AUTOSAR XML (schema 4-2-2)
standard types defined: void, boolean, sint8, sint16, sint32, sint64, uint8, uint16, uint32, uint64, float32, float64
package /Components/PhysicalDimensions
  physical dimension PhysicalDimension_None: length-exp=0.0, mass-exp=0.0, time-exp=0.0, current-exp=0.0, temperature-exp=0.0, molar-amount-exp=0.0, luminous-intensity-exp=0.0
package /Components/Units
  unit Unit_None: display-name=-, factor-si-to-unit=1.0, offset-si-to-unit=0.0, physical-dimension=PhysicalDimension_None
package /Components/ApplicationTypes
  32 x app type, all with compu {phys=raw for raw 0}, range raw 0, unit=-:
    wLoad_Type_{1..7}: category=VALUE
    wLoad_Type_8: category=BOOLEAN
    wLoad_Type_{9..15}: category=VALUE
    wLoad_Type_16: category=BOOLEAN
    AMOS_APP4UCU_Type_{17..23}: category=VALUE
    AMOS_APP4UCU_Type_24: category=BOOLEAN
    AMOS_APP4UCU_Type_{25..31}: category=VALUE
    AMOS_APP4UCU_Type_32: category=BOOLEAN
package /Components/TypeMappings
  data type mapping set TypeMapping
    data-type-maps:
      application-data-type=wLoad_Type_1, implementation-data-type=uint8
      application-data-type=wLoad_Type_2, implementation-data-type=sint8
      application-data-type=wLoad_Type_3, implementation-data-type=uint16
      application-data-type=wLoad_Type_4, implementation-data-type=sint16
      application-data-type=wLoad_Type_5, implementation-data-type=uint32
      application-data-type=wLoad_Type_6, implementation-data-type=sint32
      application-data-type=wLoad_Type_7, implementation-data-type=float32
      application-data-type=wLoad_Type_8, implementation-data-type=boolean
      application-data-type=wLoad_Type_9, implementation-data-type=uint8
      application-data-type=wLoad_Type_10, implementation-data-type=sint8
      application-data-type=wLoad_Type_11, implementation-data-type=uint16
      application-data-type=wLoad_Type_12, implementation-data-type=sint16
      application-data-type=wLoad_Type_13, implementation-data-type=uint32
      application-data-type=wLoad_Type_14, implementation-data-type=sint32
      application-data-type=wLoad_Type_15, implementation-data-type=float32
      application-data-type=wLoad_Type_16, implementation-data-type=boolean
      application-data-type=AMOS_APP4UCU_Type_17, implementation-data-type=uint8
      application-data-type=AMOS_APP4UCU_Type_18, implementation-data-type=sint8
      application-data-type=AMOS_APP4UCU_Type_19, implementation-data-type=uint16
      application-data-type=AMOS_APP4UCU_Type_20, implementation-data-type=sint16
      application-data-type=AMOS_APP4UCU_Type_21, implementation-data-type=uint32
      application-data-type=AMOS_APP4UCU_Type_22, implementation-data-type=sint32
      application-data-type=AMOS_APP4UCU_Type_23, implementation-data-type=float32
      application-data-type=AMOS_APP4UCU_Type_24, implementation-data-type=boolean
      application-data-type=AMOS_APP4UCU_Type_25, implementation-data-type=uint8
      application-data-type=AMOS_APP4UCU_Type_26, implementation-data-type=sint8
      application-data-type=AMOS_APP4UCU_Type_27, implementation-data-type=uint16
      application-data-type=AMOS_APP4UCU_Type_28, implementation-data-type=sint16
      application-data-type=AMOS_APP4UCU_Type_29, implementation-data-type=uint32
      application-data-type=AMOS_APP4UCU_Type_30, implementation-data-type=sint32
      application-data-type=AMOS_APP4UCU_Type_31, implementation-data-type=float32
      application-data-type=AMOS_APP4UCU_Type_32, implementation-data-type=boolean
package /Components/PortInterfaces
  4 x sender receiver interface:
    wLoad_toApp
      8 x data, all with sw-calibration-access=READ-ONLY:
        test_u8: type=wLoad_Type_1
        test_i8: type=wLoad_Type_2
        test_u16: type=wLoad_Type_3
        test_i16: type=wLoad_Type_4
        test_u32: type=wLoad_Type_5
        test_i32: type=wLoad_Type_6
        test_r32: type=wLoad_Type_7
        test_b: type=wLoad_Type_8
    wLoad_fromApp
      8 x data, all with sw-calibration-access=READ-ONLY:
        test_u8: type=wLoad_Type_9
        test_i8: type=wLoad_Type_10
        test_u16: type=wLoad_Type_11
        test_i16: type=wLoad_Type_12
        test_u32: type=wLoad_Type_13
        test_i32: type=wLoad_Type_14
        test_r32: type=wLoad_Type_15
        test_b: type=wLoad_Type_16
    AMOS_APP4UCU_fromApp
      8 x data, all with sw-calibration-access=READ-ONLY:
        test_u8: type=AMOS_APP4UCU_Type_17
        test_i8: type=AMOS_APP4UCU_Type_18
        test_u16: type=AMOS_APP4UCU_Type_19
        test_i16: type=AMOS_APP4UCU_Type_20
        test_u32: type=AMOS_APP4UCU_Type_21
        test_i32: type=AMOS_APP4UCU_Type_22
        test_r32: type=AMOS_APP4UCU_Type_23
        test_b: type=AMOS_APP4UCU_Type_24
    AMOS_APP4UCU_toApp
      8 x data, all with sw-calibration-access=READ-ONLY:
        test_u8: type=AMOS_APP4UCU_Type_25
        test_i8: type=AMOS_APP4UCU_Type_26
        test_u16: type=AMOS_APP4UCU_Type_27
        test_i16: type=AMOS_APP4UCU_Type_28
        test_u32: type=AMOS_APP4UCU_Type_29
        test_i32: type=AMOS_APP4UCU_Type_30
        test_r32: type=AMOS_APP4UCU_Type_31
        test_b: type=AMOS_APP4UCU_Type_32
package /Components/Components
  application sw component type IOHwAb_C0
    behavior InternalBehavior: data-type-mapping=TypeMapping, handle-termination-and-restart=NO-SUPPORT
      init event Event_IOHwAb_C0_Init: start-on-event=IOHwAb_C0_Init
      timing event Event_IOHwAb_C0_Cyclic: start-on-event=IOHwAb_C0_Cyclic, period=0.001
      timing event Event_IOHwAb_C0_Cyclic_Fast: start-on-event=IOHwAb_C0_Cyclic_Fast, period=0.0001
      runnable IOHwAb_C0_Init: symbol=IOHwAb_C0_IOHwAb_C0_Init
      runnable IOHwAb_C0_Cyclic: symbol=IOHwAb_C0_IOHwAb_C0_Cyclic
      runnable IOHwAb_C0_Cyclic_Fast: symbol=IOHwAb_C0_IOHwAb_C0_Cyclic_Fast
  swc implementation IOHwAb_C0_Implementation: sw-version=0.0.0, vendor-id=0, behavior=IOHwAb_C0/InternalBehavior
    code-descriptors:
      code CodeDescriptor: artifact-descriptors=autosar-engineering-object={short-label=CodeObject, category=SWOBJ}
    resource consumption ResourceConsumption
      memory section CODE: sw-addrmethod=CODE
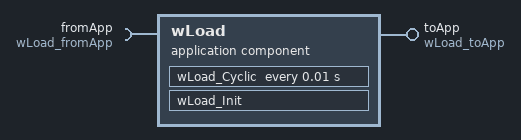
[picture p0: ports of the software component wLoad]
  application sw component type wLoad
    provide port toApp: provided-interface=wLoad_toApp
      provided-com-specs:
        data-element=wLoad_toApp/test_u8, init-value=0
        data-element=wLoad_toApp/test_i8, init-value=0
        data-element=wLoad_toApp/test_u16, init-value=0
        data-element=wLoad_toApp/test_i16, init-value=0
        data-element=wLoad_toApp/test_u32, init-value=0
        data-element=wLoad_toApp/test_i32, init-value=0
        data-element=wLoad_toApp/test_r32, init-value=0
        data-element=wLoad_toApp/test_b, init-value=0
    require port fromApp: required-interface=wLoad_fromApp
      required-com-specs:
        data-element=wLoad_fromApp/test_u8, handle-out-of-range-status=SILENT, filter=data-filter-type=ALWAYS, init-value=0
        data-element=wLoad_fromApp/test_i8, handle-out-of-range-status=SILENT, filter=data-filter-type=ALWAYS, init-value=0
        data-element=wLoad_fromApp/test_u16, handle-out-of-range-status=SILENT, filter=data-filter-type=ALWAYS, init-value=0
        data-element=wLoad_fromApp/test_i16, handle-out-of-range-status=SILENT, filter=data-filter-type=ALWAYS, init-value=0
        data-element=wLoad_fromApp/test_u32, handle-out-of-range-status=SILENT, filter=data-filter-type=ALWAYS, init-value=0
        data-element=wLoad_fromApp/test_i32, handle-out-of-range-status=SILENT, filter=data-filter-type=ALWAYS, init-value=0
        data-element=wLoad_fromApp/test_r32, handle-out-of-range-status=SILENT, filter=data-filter-type=ALWAYS, init-value=0
        data-element=wLoad_fromApp/test_b, handle-out-of-range-status=SILENT, filter=data-filter-type=ALWAYS, init-value=0
    behavior InternalBehavior: data-type-mapping=TypeMapping, handle-termination-and-restart=NO-SUPPORT
      init event Event_wLoad_Init: start-on-event=wLoad_Init
      timing event Event_wLoad_Cyclic: start-on-event=wLoad_Cyclic, period=0.01
      runnable wLoad_Init: symbol=wLoad_wLoad_Init
        data-receive-point-by-arguments:
          8 x access:
            ReceivePoint_fromApp_test_u8: accessed-variable=fromApp.test_u8
            ReceivePoint_fromApp_test_i8: accessed-variable=fromApp.test_i8
            ReceivePoint_fromApp_test_u16: accessed-variable=fromApp.test_u16
            ReceivePoint_fromApp_test_i16: accessed-variable=fromApp.test_i16
            ReceivePoint_fromApp_test_u32: accessed-variable=fromApp.test_u32
            ReceivePoint_fromApp_test_i32: accessed-variable=fromApp.test_i32
            ReceivePoint_fromApp_test_r32: accessed-variable=fromApp.test_r32
            ReceivePoint_fromApp_test_b: accessed-variable=fromApp.test_b
        data-send-points:
          8 x access:
            SendPoint_toApp_test_u8: accessed-variable=toApp.test_u8
            SendPoint_toApp_test_i8: accessed-variable=toApp.test_i8
            SendPoint_toApp_test_u16: accessed-variable=toApp.test_u16
            SendPoint_toApp_test_i16: accessed-variable=toApp.test_i16
            SendPoint_toApp_test_u32: accessed-variable=toApp.test_u32
            SendPoint_toApp_test_i32: accessed-variable=toApp.test_i32
            SendPoint_toApp_test_r32: accessed-variable=toApp.test_r32
            SendPoint_toApp_test_b: accessed-variable=toApp.test_b
      runnable wLoad_Cyclic: symbol=wLoad_wLoad_Cyclic
        data-receive-point-by-arguments:
          8 x access:
            ReceivePoint_fromApp_test_u8: accessed-variable=fromApp.test_u8
            ReceivePoint_fromApp_test_i8: accessed-variable=fromApp.test_i8
            ReceivePoint_fromApp_test_u16: accessed-variable=fromApp.test_u16
            ReceivePoint_fromApp_test_i16: accessed-variable=fromApp.test_i16
            ReceivePoint_fromApp_test_u32: accessed-variable=fromApp.test_u32
            ReceivePoint_fromApp_test_i32: accessed-variable=fromApp.test_i32
            ReceivePoint_fromApp_test_r32: accessed-variable=fromApp.test_r32
            ReceivePoint_fromApp_test_b: accessed-variable=fromApp.test_b
        data-send-points:
          8 x access:
            SendPoint_toApp_test_u8: accessed-variable=toApp.test_u8
            SendPoint_toApp_test_i8: accessed-variable=toApp.test_i8
            SendPoint_toApp_test_u16: accessed-variable=toApp.test_u16
            SendPoint_toApp_test_i16: accessed-variable=toApp.test_i16
            SendPoint_toApp_test_u32: accessed-variable=toApp.test_u32
            SendPoint_toApp_test_i32: accessed-variable=toApp.test_i32
            SendPoint_toApp_test_r32: accessed-variable=toApp.test_r32
            SendPoint_toApp_test_b: accessed-variable=toApp.test_b
  swc implementation wLoad_Implementation: sw-version=0.0.0, vendor-id=0, behavior=wLoad/InternalBehavior
    code-descriptors:
      code CodeDescriptor: artifact-descriptors=autosar-engineering-object={short-label=CodeObject, category=SWOBJ}
    resource consumption ResourceConsumption
      memory section CODE: sw-addrmethod=CODE
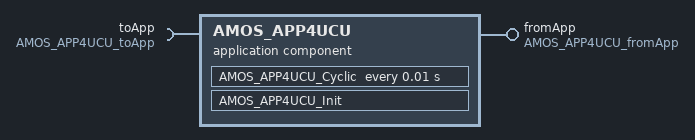
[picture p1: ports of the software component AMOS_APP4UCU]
  application sw component type AMOS_APP4UCU
    provide port fromApp: provided-interface=AMOS_APP4UCU_fromApp
      provided-com-specs:
        data-element=AMOS_APP4UCU_fromApp/test_u8, init-value=0
        data-element=AMOS_APP4UCU_fromApp/test_i8, init-value=0
        data-element=AMOS_APP4UCU_fromApp/test_u16, init-value=0
        data-element=AMOS_APP4UCU_fromApp/test_i16, init-value=0
        data-element=AMOS_APP4UCU_fromApp/test_u32, init-value=0
        data-element=AMOS_APP4UCU_fromApp/test_i32, init-value=0
        data-element=AMOS_APP4UCU_fromApp/test_r32, init-value=0
        data-element=AMOS_APP4UCU_fromApp/test_b, init-value=0
    require port toApp: required-interface=AMOS_APP4UCU_toApp
      required-com-specs:
        data-element=AMOS_APP4UCU_toApp/test_u8, handle-out-of-range-status=SILENT, filter=data-filter-type=ALWAYS, init-value=0
        data-element=AMOS_APP4UCU_toApp/test_i8, handle-out-of-range-status=SILENT, filter=data-filter-type=ALWAYS, init-value=0
        data-element=AMOS_APP4UCU_toApp/test_u16, handle-out-of-range-status=SILENT, filter=data-filter-type=ALWAYS, init-value=0
        data-element=AMOS_APP4UCU_toApp/test_i16, handle-out-of-range-status=SILENT, filter=data-filter-type=ALWAYS, init-value=0
        data-element=AMOS_APP4UCU_toApp/test_u32, handle-out-of-range-status=SILENT, filter=data-filter-type=ALWAYS, init-value=0
        data-element=AMOS_APP4UCU_toApp/test_i32, handle-out-of-range-status=SILENT, filter=data-filter-type=ALWAYS, init-value=0
        data-element=AMOS_APP4UCU_toApp/test_r32, handle-out-of-range-status=SILENT, filter=data-filter-type=ALWAYS, init-value=0
        data-element=AMOS_APP4UCU_toApp/test_b, handle-out-of-range-status=SILENT, filter=data-filter-type=ALWAYS, init-value=0
    behavior InternalBehavior: data-type-mapping=TypeMapping, handle-termination-and-restart=NO-SUPPORT
      init event Event_AMOS_APP4UCU_Init: start-on-event=AMOS_APP4UCU_Init
      timing event Event_AMOS_APP4UCU_Cyclic: start-on-event=AMOS_APP4UCU_Cyclic, period=0.01
      runnable AMOS_APP4UCU_Init: symbol=AMOS_APP4UCU_AMOS_APP4UCU_Init
        data-receive-point-by-arguments:
          8 x access:
            ReceivePoint_toApp_test_u8: accessed-variable=toApp.test_u8
            ReceivePoint_toApp_test_i8: accessed-variable=toApp.test_i8
            ReceivePoint_toApp_test_u16: accessed-variable=toApp.test_u16
            ReceivePoint_toApp_test_i16: accessed-variable=toApp.test_i16
            ReceivePoint_toApp_test_u32: accessed-variable=toApp.test_u32
            ReceivePoint_toApp_test_i32: accessed-variable=toApp.test_i32
            ReceivePoint_toApp_test_r32: accessed-variable=toApp.test_r32
            ReceivePoint_toApp_test_b: accessed-variable=toApp.test_b
        data-send-points:
          8 x access:
            SendPoint_fromApp_test_u8: accessed-variable=fromApp.test_u8
            SendPoint_fromApp_test_i8: accessed-variable=fromApp.test_i8
            SendPoint_fromApp_test_u16: accessed-variable=fromApp.test_u16
            SendPoint_fromApp_test_i16: accessed-variable=fromApp.test_i16
            SendPoint_fromApp_test_u32: accessed-variable=fromApp.test_u32
            SendPoint_fromApp_test_i32: accessed-variable=fromApp.test_i32
            SendPoint_fromApp_test_r32: accessed-variable=fromApp.test_r32
            SendPoint_fromApp_test_b: accessed-variable=fromApp.test_b
      runnable AMOS_APP4UCU_Cyclic: symbol=AMOS_APP4UCU_AMOS_APP4UCU_Cyclic
        data-receive-point-by-arguments:
          8 x access:
            ReceivePoint_toApp_test_u8: accessed-variable=toApp.test_u8
            ReceivePoint_toApp_test_i8: accessed-variable=toApp.test_i8
            ReceivePoint_toApp_test_u16: accessed-variable=toApp.test_u16
            ReceivePoint_toApp_test_i16: accessed-variable=toApp.test_i16
            ReceivePoint_toApp_test_u32: accessed-variable=toApp.test_u32
            ReceivePoint_toApp_test_i32: accessed-variable=toApp.test_i32
            ReceivePoint_toApp_test_r32: accessed-variable=toApp.test_r32
            ReceivePoint_toApp_test_b: accessed-variable=toApp.test_b
        data-send-points:
          8 x access:
            SendPoint_fromApp_test_u8: accessed-variable=fromApp.test_u8
            SendPoint_fromApp_test_i8: accessed-variable=fromApp.test_i8
            SendPoint_fromApp_test_u16: accessed-variable=fromApp.test_u16
            SendPoint_fromApp_test_i16: accessed-variable=fromApp.test_i16
            SendPoint_fromApp_test_u32: accessed-variable=fromApp.test_u32
            SendPoint_fromApp_test_i32: accessed-variable=fromApp.test_i32
            SendPoint_fromApp_test_r32: accessed-variable=fromApp.test_r32
            SendPoint_fromApp_test_b: accessed-variable=fromApp.test_b
  swc implementation AMOS_APP4UCU_Implementation: sw-version=0.0.0, vendor-id=0, behavior=AMOS_APP4UCU/InternalBehavior
    code-descriptors:
      code CodeDescriptor: artifact-descriptors=autosar-engineering-object={short-label=CodeObject, category=SWOBJ}
    resource consumption ResourceConsumption
      memory section CODE: sw-addrmethod=CODE
